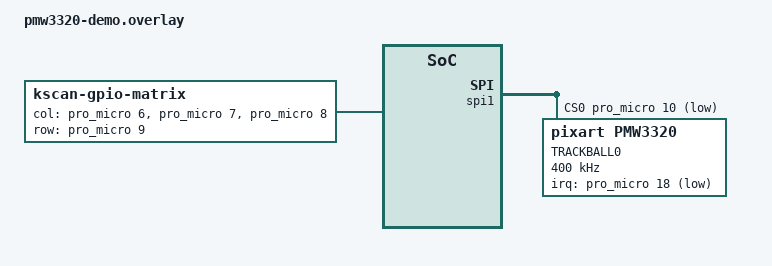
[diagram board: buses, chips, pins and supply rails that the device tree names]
/*
 * Copyright (c) 2025 Alyx
 *
 * SPDX-License-Identifier: MIT
 */

#include <dt-bindings/zmk/matrix_transform.h>
#include <zephyr/dt-bindings/input/input-event-codes.h>

&spi1 {
  compatible = "nordic,nrf-spim";
	status = "okay";
	cs-gpios = <&pro_micro 10 GPIO_ACTIVE_LOW>;
  pinctrl-0 = <&spi1_default>;
  pinctrl-1 = <&spi1_sleep>;
  pinctrl-names = "default", "sleep";
	trackball: trackball@0 {
		compatible = "pixart,pmw3320";
		status = "okay";
		label = "TRACKBALL0";
		reg = <0>;
		spi-max-frequency = <400000>;
  	irq-gpios = <&pro_micro 18 (GPIO_ACTIVE_LOW | GPIO_PULL_UP)>;
  	cpi = <250>;
  	evt-type = <INPUT_EV_REL>;
  	x-input-code = <INPUT_REL_X>;
	  y-input-code = <INPUT_REL_Y>;
	};
};

/ {
  trackball_listener {
    compatible = "zmk,input-listener";
    device = <&trackball>;
  };

	chosen {
		zmk,kscan = &kscan0;
		zmk,matrix-transform = &default_transform;
	};

	default_transform: keymap_transform_0 {
		compatible = "zmk,matrix-transform";
		columns = <3>;
		rows = <1>;
		map = <
			RC(0,0) RC(0,1) RC(0,2) 
		>;
	};

	kscan0: kscan {
		compatible = "zmk,kscan-gpio-matrix";
		label = "KSCAN";
		diode-direction = "col2row";
		wakeup-source;

    col-gpios
      = <&pro_micro 6 GPIO_ACTIVE_HIGH>
      , <&pro_micro 7 GPIO_ACTIVE_HIGH>
      , <&pro_micro 8 GPIO_ACTIVE_HIGH>
      ;

		row-gpios
			= <&pro_micro 9 (GPIO_ACTIVE_HIGH | GPIO_PULL_DOWN)>
			;
	};
};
